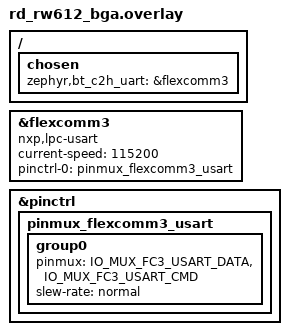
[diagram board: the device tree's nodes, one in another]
/* SPDX-License-Identifier: Apache-2.0 */

/ {
	chosen {
		zephyr,bt_c2h_uart = &flexcomm3;
	};
};

&flexcomm3 {
	compatible = "nxp,lpc-usart";
	status = "okay";
	current-speed = <115200>;
	pinctrl-0 = <&pinmux_flexcomm3_usart>;
	pinctrl-names = "default";
};

&pinctrl {
	pinmux_flexcomm3_usart: pinmux_flexcomm3_usart {
		group0 {
			pinmux = <IO_MUX_FC3_USART_DATA>, <IO_MUX_FC3_USART_CMD>;
			slew-rate = "normal";
		};
	};
};
